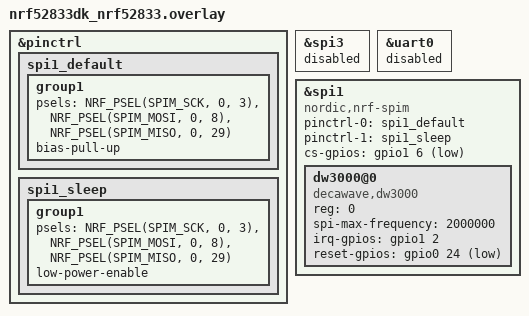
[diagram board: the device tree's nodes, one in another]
&pinctrl {
    /* Configuration des pins pour SPI1 */
    spi1_default: spi1_default {
        group1 {
            /* Mapping conforme au schéma DWM3001C Page 3 */
            psels = <NRF_PSEL(SPIM_SCK, 0, 3)>,   /* CLK  : P0.03 */
                    <NRF_PSEL(SPIM_MOSI, 0, 8)>,  /* MOSI : P0.08 */
                    <NRF_PSEL(SPIM_MISO, 0, 29)>; /* MISO : P0.29 */
            bias-pull-up; /* Sécurité sur MISO */
        };
    };

    spi1_sleep: spi1_sleep {
        group1 {
            psels = <NRF_PSEL(SPIM_SCK, 0, 3)>,
                    <NRF_PSEL(SPIM_MOSI, 0, 8)>,
                    <NRF_PSEL(SPIM_MISO, 0, 29)>;
            low-power-enable;
        };
    };
};

/* On désactive SPI3 et UART0 pour éviter tout conflit sur P0.08 ou P0.29 */
&spi3 { status = "disabled"; };
&uart0 { status = "disabled"; };

/* On active SPI1 avec le bon CS sur le Port 1 */
&spi1 {
    compatible = "nordic,nrf-spim";
    status = "okay";
    pinctrl-0 = <&spi1_default>;
    pinctrl-1 = <&spi1_sleep>;
    pinctrl-names = "default", "sleep";
    
    /* CS est sur le Port 1, Pin 06 */
    cs-gpios = <&gpio1 6 GPIO_ACTIVE_LOW>;

    dw3000@0 {
        compatible = "decawave,dw3000";
        status = "okay";
        reg = <0>;
        spi-max-frequency = <2000000>; /* 2 MHz pour le test */
        
        /* IRQ est sur le Port 1, Pin 02 */
        irq-gpios = <&gpio1 2 GPIO_ACTIVE_HIGH>; 
        
        /* Reset reste sur P0.24 comme vu sur le schéma */
        reset-gpios = <&gpio0 24 GPIO_ACTIVE_LOW>;
    };
};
